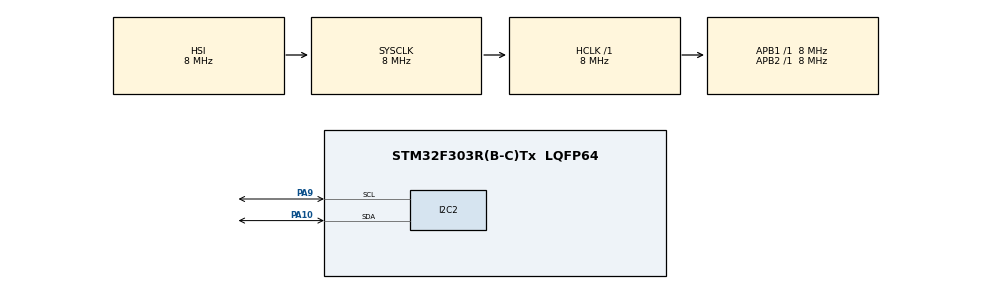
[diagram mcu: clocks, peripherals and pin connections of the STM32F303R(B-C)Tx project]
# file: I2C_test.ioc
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I2C2.Analog_Filter=I2C_ANALOGFILTER_ENABLE
I2C2.Speed=40
I2C2.Timing=0x00103D84
Mcu.Family=STM32F3
Mcu.Name=STM32F303R(B-C)Tx
Mcu.Package=LQFP64
NVIC.I2C2_ER_IRQn=true\:0\:0\:false\:false\:true\:true\:true
NVIC.I2C2_EV_IRQn=true\:0\:0\:false\:false\:true\:true\:true
NVIC.PriorityGroup=NVIC_PRIORITYGROUP_4
PA10.Mode=I2C
PA10.Signal=I2C2_SDA
PA9.Mode=I2C
PA9.Signal=I2C2_SCL
ProjectManager.HeapSize=0x200
ProjectManager.StackSize=0x400
ProjectManager.TargetToolchain=STM32CubeIDE
RCC.AHBFreq_Value=8000000
RCC.APB1Freq_Value=8000000
RCC.APB2Freq_Value=8000000
RCC.CortexFreq_Value=8000000
RCC.HSE_VALUE=8000000
RCC.HSI_VALUE=8000000
RCC.LSE_VALUE=32768
RCC.SYSCLKFreq_VALUE=8000000
VP_IWDG_VS_IWDG.Mode=IWDG_Activate
board=custom

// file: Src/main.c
/* USER CODE BEGIN Header */
/**
  ******************************************************************************
  * @file           : main.c
  * @brief          : Main program body
  ******************************************************************************
  * @attention
  *
  * <h2><center>&copy; Copyright (c) 2020 STMicroelectronics.
  * All rights reserved.</center></h2>
  *
  * This software component is licensed by ST under BSD 3-Clause license,
  * the "License"; You may not use this file except in compliance with the
  * License. You may obtain a copy of the License at:
  *                        opensource.org/licenses/BSD-3-Clause
  *
  ******************************************************************************
  */
/* USER CODE END Header */

#include "main.h"

/* USER CODE BEGIN PM */
volatile uint8_t	ExchangeFinish			=1;
volatile uint8_t	WaitReg					=0;
volatile uint8_t	Reg						=1;
volatile uint8_t	RegSize					=2;
volatile uint16_t	RegData_WriteToSlave	=0;
volatile uint16_t	RegData_WriteToMaster	=0;

/* USER CODE END PM */

I2C_HandleTypeDef hi2c2;

IWDG_HandleTypeDef hiwdg;

void SystemClock_Config(void);
static void MX_GPIO_Init(void);
static void MX_I2C2_Init(void);
static void MX_IWDG_Init(void);

int main(void)
{

  /* MCU Configuration--------------------------------------------------------*/

  /* Reset of all peripherals, Initializes the Flash interface and the Systick. */
  HAL_Init();

  /* Configure the system clock */
  SystemClock_Config();

  /* Initialize all configured peripherals */
  MX_GPIO_Init();
  MX_I2C2_Init();
  MX_IWDG_Init();

  /* Infinite loop */
  /* USER CODE BEGIN WHILE */
  ExchangeFinish=1;
  while (1)
  {
	  if (ExchangeFinish)
	  		{
	  		while (HAL_I2C_GetState(&hi2c2) != HAL_I2C_STATE_READY) {HAL_IWDG_Refresh(&hiwdg);};

	  		if (HAL_I2C_EnableListen_IT(&hi2c2) != HAL_OK) {HAL_IWDG_Refresh(&hiwdg);};
	  		}
    /* USER CODE END WHILE */

  }
}

void SystemClock_Config(void)
{
  RCC_OscInitTypeDef RCC_OscInitStruct = {0};
  RCC_ClkInitTypeDef RCC_ClkInitStruct = {0};
  RCC_PeriphCLKInitTypeDef PeriphClkInit = {0};

  /** Initializes the CPU, AHB and APB busses clocks
  */
  RCC_OscInitStruct.OscillatorType = RCC_OSCILLATORTYPE_HSI|RCC_OSCILLATORTYPE_LSI;
  RCC_OscInitStruct.HSIState = RCC_HSI_ON;
  RCC_OscInitStruct.HSICalibrationValue = RCC_HSICALIBRATION_DEFAULT;
  RCC_OscInitStruct.LSIState = RCC_LSI_ON;
  RCC_OscInitStruct.PLL.PLLState = RCC_PLL_NONE;
  if (HAL_RCC_OscConfig(&RCC_OscInitStruct) != HAL_OK)
  {
    Error_Handler();
  }
  /** Initializes the CPU, AHB and APB busses clocks
  */
  RCC_ClkInitStruct.ClockType = RCC_CLOCKTYPE_HCLK|RCC_CLOCKTYPE_SYSCLK
                              |RCC_CLOCKTYPE_PCLK1|RCC_CLOCKTYPE_PCLK2;
  RCC_ClkInitStruct.SYSCLKSource = RCC_SYSCLKSOURCE_HSI;
  RCC_ClkInitStruct.AHBCLKDivider = RCC_SYSCLK_DIV1;
  RCC_ClkInitStruct.APB1CLKDivider = RCC_HCLK_DIV1;
  RCC_ClkInitStruct.APB2CLKDivider = RCC_HCLK_DIV1;

  if (HAL_RCC_ClockConfig(&RCC_ClkInitStruct, FLASH_LATENCY_0) != HAL_OK)
  {
    Error_Handler();
  }
  PeriphClkInit.PeriphClockSelection = RCC_PERIPHCLK_I2C2;
  PeriphClkInit.I2c2ClockSelection = RCC_I2C2CLKSOURCE_HSI;
  if (HAL_RCCEx_PeriphCLKConfig(&PeriphClkInit) != HAL_OK)
  {
    Error_Handler();
  }
}

static void MX_I2C2_Init(void)
{

  hi2c2.Instance = I2C2;
  hi2c2.Init.Timing = 0x00103D84;
  hi2c2.Init.OwnAddress1 = 0x33;
  hi2c2.Init.AddressingMode = I2C_ADDRESSINGMODE_7BIT;
  hi2c2.Init.DualAddressMode = I2C_DUALADDRESS_DISABLE;
  hi2c2.Init.OwnAddress2 = 0;
  hi2c2.Init.OwnAddress2Masks = I2C_OA2_NOMASK;
  hi2c2.Init.GeneralCallMode = I2C_GENERALCALL_DISABLE;
  hi2c2.Init.NoStretchMode = I2C_NOSTRETCH_DISABLE;
  if (HAL_I2C_Init(&hi2c2) != HAL_OK)
  {
    Error_Handler();
  }
  /** Configure Analogue filter
  */
  if (HAL_I2CEx_ConfigAnalogFilter(&hi2c2, I2C_ANALOGFILTER_ENABLE) != HAL_OK)
  {
    Error_Handler();
  }
  /** Configure Digital filter
  */
  if (HAL_I2CEx_ConfigDigitalFilter(&hi2c2, 0) != HAL_OK)
  {
    Error_Handler();
  }

}

static void MX_IWDG_Init(void)
{

  hiwdg.Instance = IWDG;
  hiwdg.Init.Prescaler = IWDG_PRESCALER_4;
  hiwdg.Init.Window = 4095;
  hiwdg.Init.Reload = 4095;
  if (HAL_IWDG_Init(&hiwdg) != HAL_OK)
  {
    Error_Handler();
  }

}

static void MX_GPIO_Init(void)
{

  /* GPIO Ports Clock Enable */
  __HAL_RCC_GPIOA_CLK_ENABLE();

}

/* USER CODE BEGIN 4 */
void HAL_I2C_AddrCallback(I2C_HandleTypeDef *hi2c, uint8_t TransferDirection, uint16_t AddrMatchCode) {
	UNUSED(AddrMatchCode);

	if (hi2c->Instance == I2C2)
		{
		//transferRequested	= 1;
		WaitReg=1;
		ExchangeFinish=0;

		switch (TransferDirection)
			{
			case I2C_DIRECTION_RECEIVE:
				HAL_I2C_Slave_Seq_Transmit_IT(&hi2c2, (uint8_t *)&RegData_WriteToMaster, RegSize, I2C_LAST_FRAME);
				break;
			case I2C_DIRECTION_TRANSMIT:
				HAL_I2C_Slave_Seq_Receive_IT (&hi2c2, (uint8_t *)&Reg, 1, I2C_FIRST_FRAME);
				break;
			};
		};
}
void HAL_I2C_SlaveRxCpltCallback(I2C_HandleTypeDef *hi2c)
{
	static volatile HAL_StatusTypeDef Res;

	if (WaitReg)
		{
		WaitReg=0;

		switch(Reg)
			{
			case  1: RegSize=2; RegData_WriteToMaster=(uint16_t)200;					break;
			default: RegSize=2; RegData_WriteToMaster=10; break;
			};

		RegData_WriteToSlave=0;
		HAL_I2C_Slave_Seq_Receive_IT(&hi2c2, (uint8_t *)&RegData_WriteToSlave, RegSize, I2C_LAST_FRAME);
		}
	else
		{
		ExchangeFinish=1;

		switch(Reg)
			{
			//case  1: Control.HLK_Heat_PWMCurrentControl	=(int16_t)	RegData_WriteToSlave;						break;
			};
		};

	UNUSED(Res);
}
void HAL_I2C_SlaveTxCpltCallback(I2C_HandleTypeDef *hi2c)
{
	ExchangeFinish=1;

	UNUSED(hi2c);
}

void HAL_I2C_ListenCpltCallback(I2C_HandleTypeDef *hi2c)
{
	ExchangeFinish=1;

	UNUSED(hi2c);
}

void HAL_I2C_ErrorCallback(I2C_HandleTypeDef *hi2c)
{
	ExchangeFinish=1;

	UNUSED(hi2c);
}
/* USER CODE END 4 */

void Error_Handler(void)
{
}

/************************ (C) COPYRIGHT STMicroelectronics *****END OF FILE****/
